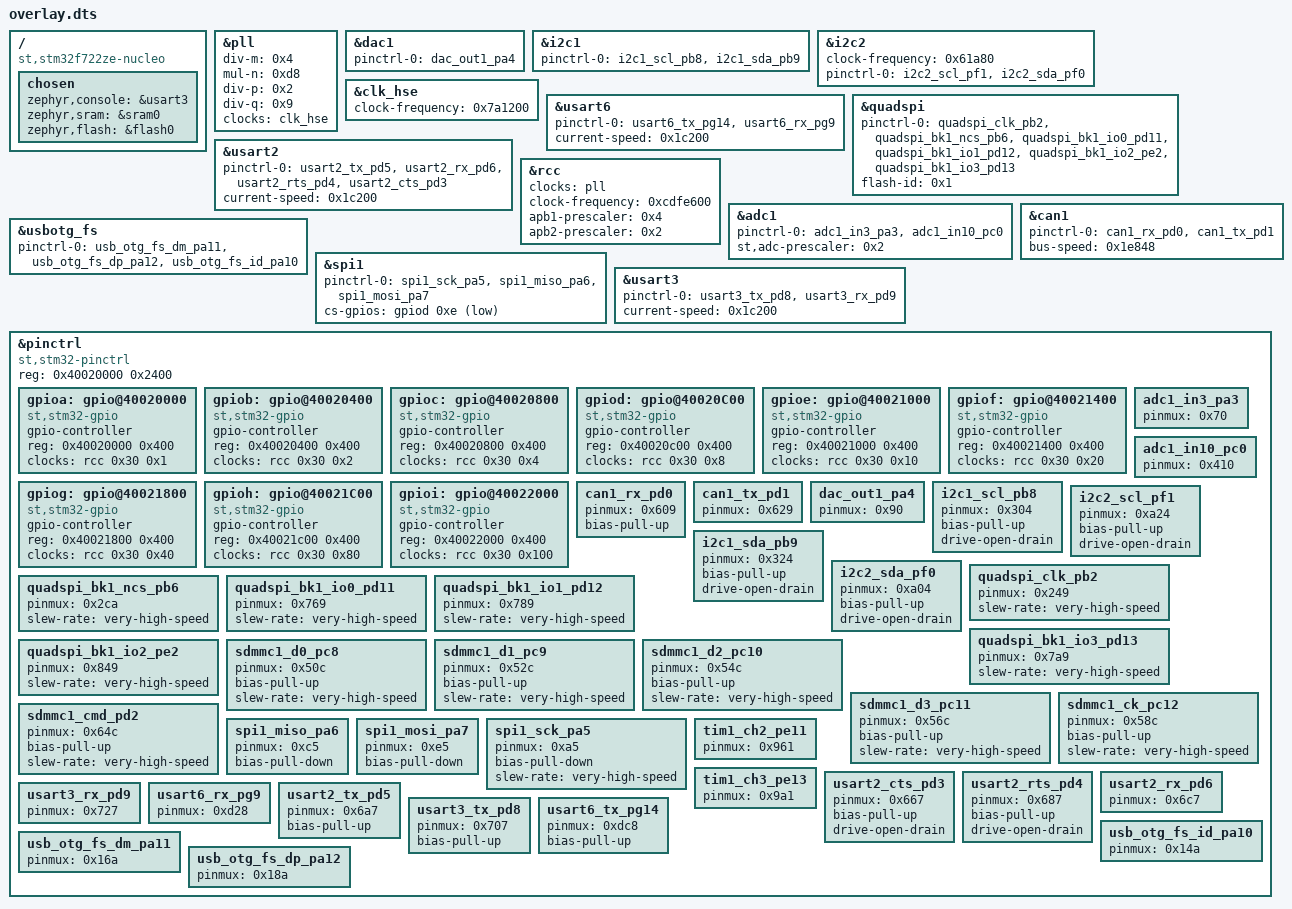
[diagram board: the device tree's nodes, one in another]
/ {
	compatible = "st,stm32f722ze-nucleo";
	chosen {
		zephyr,console = &usart3;
		zephyr,sram = &sram0;
		zephyr,flash = &flash0;
	};
};
&pll{
	status = "okay";
	div-m = < 0x4 >;
	mul-n = < 0xd8 >;
	div-p = < 0x2 >;
	div-q = < 0x9 >;
	clocks = < &clk_hse >;
};
&dac1{
	status = "okay";
	pinctrl-0 = < &dac_out1_pa4 >;
	pinctrl-names = "default";
};
&i2c1{
	status = "okay";
	pinctrl-0 = < &i2c1_scl_pb8 &i2c1_sda_pb9 >;
	pinctrl-names = "default";
};
&i2c2{
	clock-frequency = < 0x61a80 >;
	status = "okay";
	pinctrl-0 = < &i2c2_scl_pf1 &i2c2_sda_pf0 >;
	pinctrl-names = "default";
};
&clk_hse{
	status = "okay";
	clock-frequency = < 0x7a1200 >;
};
&usart6{
	status = "okay";
	pinctrl-0 = < &usart6_tx_pg14 &usart6_rx_pg9 >;
	pinctrl-names = "default";
	current-speed = < 0x1c200 >;
};
&quadspi{
	status = "okay";
	pinctrl-names = "default";
	pinctrl-0 = < &quadspi_clk_pb2 &quadspi_bk1_ncs_pb6 &quadspi_bk1_io0_pd11 &quadspi_bk1_io1_pd12 &quadspi_bk1_io2_pe2 &quadspi_bk1_io3_pd13 >;
	flash-id = < 0x1 >;
};
&usart2{
	status = "okay";
	pinctrl-0 = < &usart2_tx_pd5 &usart2_rx_pd6 &usart2_rts_pd4 &usart2_cts_pd3 >;
	pinctrl-names = "default";
	current-speed = < 0x1c200 >;
};
&rcc{
	clocks = < &pll >;
	clock-frequency = < 0xcdfe600 >;
	apb1-prescaler = < 0x4 >;
	apb2-prescaler = < 0x2 >;
};
&adc1{
	status = "okay";
	pinctrl-0 = < &adc1_in3_pa3 &adc1_in10_pc0 >;
	pinctrl-names = "default";
	st,adc-prescaler = < 0x2 >;
};
&usbotg_fs{
	status = "okay";
	pinctrl-0 = < &usb_otg_fs_dm_pa11 &usb_otg_fs_dp_pa12 &usb_otg_fs_id_pa10 >;
	pinctrl-names = "default";
};
&can1{
	status = "okay";
	pinctrl-0 = < &can1_rx_pd0 &can1_tx_pd1 >;
	pinctrl-names = "default";
	bus-speed = < 0x1e848 >;
};
&spi1{
	status = "okay";
	pinctrl-0 = < &spi1_sck_pa5 &spi1_miso_pa6 &spi1_mosi_pa7 >;
	pinctrl-names = "default";
	cs-gpios = < &gpiod 0xe 0x11 >;
};
&usart3{
	status = "okay";
	pinctrl-0 = < &usart3_tx_pd8 &usart3_rx_pd9 >;
	pinctrl-names = "default";
	current-speed = < 0x1c200 >;
};
&pinctrl{
	compatible = "st,stm32-pinctrl";
	#address-cells = < 0x1 >;
	#size-cells = < 0x1 >;
	reg = < 0x40020000 0x2400 >;
	gpioa: gpio@40020000 {
		compatible = "st,stm32-gpio";
		gpio-controller;
		#gpio-cells = < 0x2 >;
		reg = < 0x40020000 0x400 >;
		clocks = < &rcc 0x30 0x1 >;
	};
	gpiob: gpio@40020400 {
		compatible = "st,stm32-gpio";
		gpio-controller;
		#gpio-cells = < 0x2 >;
		reg = < 0x40020400 0x400 >;
		clocks = < &rcc 0x30 0x2 >;
	};
	gpioc: gpio@40020800 {
		compatible = "st,stm32-gpio";
		gpio-controller;
		#gpio-cells = < 0x2 >;
		reg = < 0x40020800 0x400 >;
		clocks = < &rcc 0x30 0x4 >;
	};
	gpiod: gpio@40020C00 {
		compatible = "st,stm32-gpio";
		gpio-controller;
		#gpio-cells = < 0x2 >;
		reg = < 0x40020c00 0x400 >;
		clocks = < &rcc 0x30 0x8 >;
	};
	gpioe: gpio@40021000 {
		compatible = "st,stm32-gpio";
		gpio-controller;
		#gpio-cells = < 0x2 >;
		reg = < 0x40021000 0x400 >;
		clocks = < &rcc 0x30 0x10 >;
	};
	gpiof: gpio@40021400 {
		compatible = "st,stm32-gpio";
		gpio-controller;
		#gpio-cells = < 0x2 >;
		reg = < 0x40021400 0x400 >;
		clocks = < &rcc 0x30 0x20 >;
	};
	gpiog: gpio@40021800 {
		compatible = "st,stm32-gpio";
		gpio-controller;
		#gpio-cells = < 0x2 >;
		reg = < 0x40021800 0x400 >;
		clocks = < &rcc 0x30 0x40 >;
	};
	gpioh: gpio@40021C00 {
		compatible = "st,stm32-gpio";
		gpio-controller;
		#gpio-cells = < 0x2 >;
		reg = < 0x40021c00 0x400 >;
		clocks = < &rcc 0x30 0x80 >;
	};
	gpioi: gpio@40022000 {
		compatible = "st,stm32-gpio";
		gpio-controller;
		#gpio-cells = < 0x2 >;
		reg = < 0x40022000 0x400 >;
		clocks = < &rcc 0x30 0x100 >;
	};
	adc1_in3_pa3: adc1_in3_pa3 {
		pinmux = < 0x70 >;
	};
	adc1_in10_pc0: adc1_in10_pc0 {
		pinmux = < 0x410 >;
	};
	can1_rx_pd0: can1_rx_pd0 {
		pinmux = < 0x609 >;
		bias-pull-up;
	};
	can1_tx_pd1: can1_tx_pd1 {
		pinmux = < 0x629 >;
	};
	dac_out1_pa4: dac_out1_pa4 {
		pinmux = < 0x90 >;
	};
	i2c1_scl_pb8: i2c1_scl_pb8 {
		pinmux = < 0x304 >;
		bias-pull-up;
		drive-open-drain;
	};
	i2c2_scl_pf1: i2c2_scl_pf1 {
		pinmux = < 0xa24 >;
		bias-pull-up;
		drive-open-drain;
	};
	i2c1_sda_pb9: i2c1_sda_pb9 {
		pinmux = < 0x324 >;
		bias-pull-up;
		drive-open-drain;
	};
	i2c2_sda_pf0: i2c2_sda_pf0 {
		pinmux = < 0xa04 >;
		bias-pull-up;
		drive-open-drain;
	};
	quadspi_clk_pb2: quadspi_clk_pb2 {
		pinmux = < 0x249 >;
		slew-rate = "very-high-speed";
	};
	quadspi_bk1_ncs_pb6: quadspi_bk1_ncs_pb6 {
		pinmux = < 0x2ca >;
		slew-rate = "very-high-speed";
	};
	quadspi_bk1_io0_pd11: quadspi_bk1_io0_pd11 {
		pinmux = < 0x769 >;
		slew-rate = "very-high-speed";
	};
	quadspi_bk1_io1_pd12: quadspi_bk1_io1_pd12 {
		pinmux = < 0x789 >;
		slew-rate = "very-high-speed";
	};
	quadspi_bk1_io3_pd13: quadspi_bk1_io3_pd13 {
		pinmux = < 0x7a9 >;
		slew-rate = "very-high-speed";
	};
	quadspi_bk1_io2_pe2: quadspi_bk1_io2_pe2 {
		pinmux = < 0x849 >;
		slew-rate = "very-high-speed";
	};
	sdmmc1_d0_pc8: sdmmc1_d0_pc8 {
		pinmux = < 0x50c >;
		bias-pull-up;
		slew-rate = "very-high-speed";
	};
	sdmmc1_d1_pc9: sdmmc1_d1_pc9 {
		pinmux = < 0x52c >;
		bias-pull-up;
		slew-rate = "very-high-speed";
	};
	sdmmc1_d2_pc10: sdmmc1_d2_pc10 {
		pinmux = < 0x54c >;
		bias-pull-up;
		slew-rate = "very-high-speed";
	};
	sdmmc1_d3_pc11: sdmmc1_d3_pc11 {
		pinmux = < 0x56c >;
		bias-pull-up;
		slew-rate = "very-high-speed";
	};
	sdmmc1_ck_pc12: sdmmc1_ck_pc12 {
		pinmux = < 0x58c >;
		bias-pull-up;
		slew-rate = "very-high-speed";
	};
	sdmmc1_cmd_pd2: sdmmc1_cmd_pd2 {
		pinmux = < 0x64c >;
		bias-pull-up;
		slew-rate = "very-high-speed";
	};
	spi1_miso_pa6: spi1_miso_pa6 {
		pinmux = < 0xc5 >;
		bias-pull-down;
	};
	spi1_mosi_pa7: spi1_mosi_pa7 {
		pinmux = < 0xe5 >;
		bias-pull-down;
	};
	spi1_sck_pa5: spi1_sck_pa5 {
		pinmux = < 0xa5 >;
		bias-pull-down;
		slew-rate = "very-high-speed";
	};
	tim1_ch2_pe11: tim1_ch2_pe11 {
		pinmux = < 0x961 >;
	};
	tim1_ch3_pe13: tim1_ch3_pe13 {
		pinmux = < 0x9a1 >;
	};
	usart2_cts_pd3: usart2_cts_pd3 {
		pinmux = < 0x667 >;
		bias-pull-up;
		drive-open-drain;
	};
	usart2_rts_pd4: usart2_rts_pd4 {
		pinmux = < 0x687 >;
		bias-pull-up;
		drive-open-drain;
	};
	usart2_rx_pd6: usart2_rx_pd6 {
		pinmux = < 0x6c7 >;
	};
	usart3_rx_pd9: usart3_rx_pd9 {
		pinmux = < 0x727 >;
	};
	usart6_rx_pg9: usart6_rx_pg9 {
		pinmux = < 0xd28 >;
	};
	usart2_tx_pd5: usart2_tx_pd5 {
		pinmux = < 0x6a7 >;
		bias-pull-up;
	};
	usart3_tx_pd8: usart3_tx_pd8 {
		pinmux = < 0x707 >;
		bias-pull-up;
	};
	usart6_tx_pg14: usart6_tx_pg14 {
		pinmux = < 0xdc8 >;
		bias-pull-up;
	};
	usb_otg_fs_id_pa10: usb_otg_fs_id_pa10 {
		pinmux = < 0x14a >;
	};
	usb_otg_fs_dm_pa11: usb_otg_fs_dm_pa11 {
		pinmux = < 0x16a >;
	};
	usb_otg_fs_dp_pa12: usb_otg_fs_dp_pa12 {
		pinmux = < 0x18a >;
	};
};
